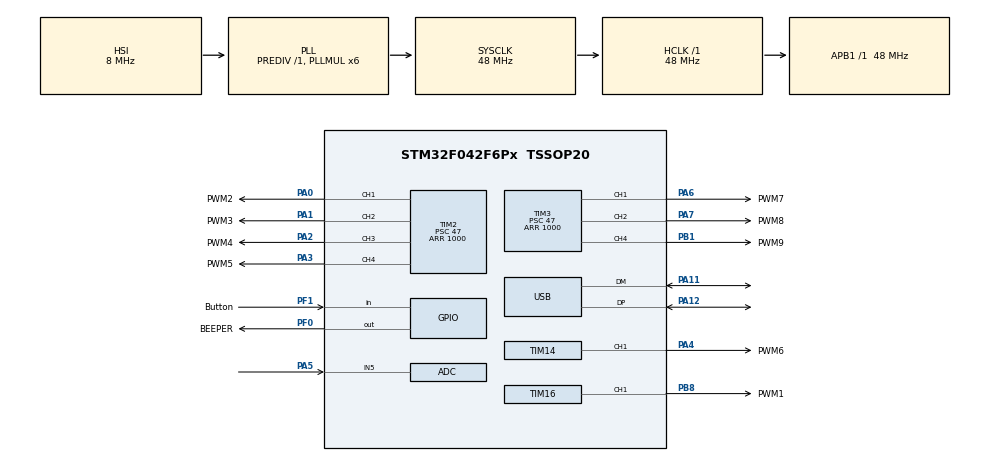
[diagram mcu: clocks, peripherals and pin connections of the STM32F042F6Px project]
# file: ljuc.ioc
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ADC.ContinuousConvMode=DISABLE
ADC.Rank=ADC_RANK_CHANNEL_NUMBER
ADC.SamplingTime=ADC_SAMPLETIME_239CYCLES_5
Dma.ADC.0.Direction=DMA_PERIPH_TO_MEMORY
Dma.ADC.0.Instance=DMA1_Channel1
Dma.ADC.0.MemDataAlignment=DMA_MDATAALIGN_WORD
Dma.ADC.0.MemInc=DMA_MINC_ENABLE
Dma.ADC.0.Mode=DMA_NORMAL
Dma.ADC.0.PeriphDataAlignment=DMA_PDATAALIGN_HALFWORD
Dma.ADC.0.PeriphInc=DMA_PINC_DISABLE
Dma.ADC.0.Priority=DMA_PRIORITY_LOW
Dma.Request0=ADC
Mcu.Family=STM32F0
Mcu.Name=STM32F042F6Px
Mcu.Package=TSSOP20
NVIC.DMA1_Channel1_IRQn=true\:0\:0\:false\:false\:true
NVIC.TIM17_IRQn=true\:0\:0\:false\:false\:true
NVIC.TIM2_IRQn=true\:0\:0\:false\:false\:true
NVIC.USB_IRQn=true\:0\:0\:false\:false\:true
PA0.GPIO_Label=PWM2
PA0.Signal=S_TIM2_CH1_ETR
PA1.GPIO_Label=PWM3
PA1.Signal=S_TIM2_CH2
PA11.Mode=Device
PA11.Signal=USB_DM
PA12.Mode=Device
PA12.Signal=USB_DP
PA13.Mode=Serial_Wire
PA13.Signal=SYS_SWDIO
PA14.Mode=Serial_Wire
PA14.Signal=SYS_SWCLK
PA2.GPIO_Label=PWM4
PA2.Signal=S_TIM2_CH3
PA3.GPIO_Label=PWM5
PA3.Signal=S_TIM2_CH4
PA4.GPIO_Label=PWM6
PA4.Signal=S_TIM14_CH1
PA5.Mode=IN5
PA5.Signal=ADC_IN5
PA6.GPIO_Label=PWM7
PA6.Signal=S_TIM3_CH1
PA7.GPIO_Label=PWM8
PA7.Signal=S_TIM3_CH2
PB1.GPIO_Label=PWM9
PB1.Signal=S_TIM3_CH4
PB8.GPIO_Label=PWM1
PB8.Signal=S_TIM16_CH1
PF0-OSC_IN.GPIO_Label=BEEPER
PF0-OSC_IN.Signal=GPIO_Output
PF1-OSC_OUT.GPIO_Label=Button
PF1-OSC_OUT.Signal=GPIO_Input
ProjectManager.HeapSize=0x200
ProjectManager.StackSize=0x400
ProjectManager.TargetToolchain=MDK-ARM V5
RCC.AHBCLKDivider=RCC_SYSCLK_DIV1
RCC.AHBFreq_Value=48000000
RCC.APB1CLKDivider=RCC_HCLK_DIV1
RCC.APB1Freq_Value=48000000
RCC.APB1TimFreq_Value=48000000
RCC.CECEnable=false
RCC.ClockTypeHCLK=RCC_CLOCKTYPE_HCLK
RCC.ClockTypePCLK1=RCC_CLOCKTYPE_PCLK1
RCC.DATA_CACHE_ENABLE=0
RCC.EnableHSE=false
RCC.EnableHSERTCDevisor=false
RCC.EnableLSE=false
RCC.EnableLSERTC=false
RCC.EnableMCOMultDivisor=false
RCC.HCLKFreq_Value=48000000
RCC.HSEState=RCC_HSE_OFF
RCC.HSI14State=RCC_HSI14_ON
RCC.HSI48State=RCC_HSI48_ON
RCC.HSIState=RCC_HSI_ON
RCC.I2C1Enable=false
RCC.INSTRUCTION_CACHE_ENABLE=0
RCC.IWDGEnable=false
RCC.LSIState=RCC_LSI_OFF
RCC.MCOEnable=false
RCC.OscillatorTypeHSI=RCC_OSCILLATORTYPE_HSI
RCC.OscillatorTypeHSI14=RCC_OSCILLATORTYPE_HSI14
RCC.OscillatorTypeHSI48=RCC_OSCILLATORTYPE_HSI48
RCC.PLLDivider=RCC_PREDIV_DIV1
RCC.PLLMUL=RCC_PLL_MUL6
RCC.PLLSource=RCC_PLLSOURCE_HSI
RCC.PLLSourceVirtual=RCC_PLLSOURCE_HSI
RCC.PLLState=RCC_PLL_ON
RCC.RTCEnable=false
RCC.SYSCLKFreq_VALUE=48000000
RCC.SYSCLKSource=RCC_SYSCLKSOURCE_PLLCLK
RCC.TimSys_Div=SYSTICK_CLKSOURCE_HCLK
RCC.USART1Enable=false
RCC.USART2Enable=false
RCC.USBClockSelection=RCC_USBCLKSOURCE_HSI48
RCC.USBEnable=true
RCC.USBFreq_Value=48000000
SH.S_TIM14_CH1.0=TIM14_CH1,PWM Generation1 CH1
SH.S_TIM16_CH1.0=TIM16_CH1,PWM Generation1 CH1
SH.S_TIM2_CH1_ETR.0=TIM2_CH1,PWM Generation1 CH1
SH.S_TIM2_CH2.0=TIM2_CH2,PWM Generation2 CH2
SH.S_TIM2_CH3.0=TIM2_CH3,PWM Generation3 CH3
SH.S_TIM2_CH4.0=TIM2_CH4,PWM Generation4 CH4
SH.S_TIM3_CH1.0=TIM3_CH1,PWM Generation1 CH1
SH.S_TIM3_CH2.0=TIM3_CH2,PWM Generation2 CH2
SH.S_TIM3_CH4.0=TIM3_CH4,PWM Generation4 CH4
TIM14.Channel=TIM_CHANNEL_1
TIM14.Period=1000
TIM14.Prescaler=47
TIM16.Channel=TIM_CHANNEL_1
TIM16.OCNIdleState_1=TIM_OCNIDLESTATE_RESET
TIM16.OCNPolarity_1=TIM_OCNPOLARITY_HIGH
TIM16.Period=1000
TIM16.Prescaler=47
TIM17.Period=9999
TIM17.Prescaler=47
TIM2.Channel-PWM\ Generation1\ CH1=TIM_CHANNEL_1
TIM2.Channel-PWM\ Generation2\ CH2=TIM_CHANNEL_2
TIM2.Channel-PWM\ Generation3\ CH3=TIM_CHANNEL_3
TIM2.Channel-PWM\ Generation4\ CH4=TIM_CHANNEL_4
TIM2.ClearInputSource=TIM_CLEARINPUTSOURCE_NONE
TIM2.ClearInputState=ENABLE
TIM2.Period=1000
TIM2.Prescaler=47
TIM3.Channel-PWM\ Generation1\ CH1=TIM_CHANNEL_1
TIM3.Channel-PWM\ Generation2\ CH2=TIM_CHANNEL_2
TIM3.Channel-PWM\ Generation4\ CH4=TIM_CHANNEL_4
TIM3.ClearInputSource=TIM_CLEARINPUTSOURCE_NONE
TIM3.ClearInputState=ENABLE
TIM3.Period=1000
TIM3.Prescaler=47
USB_DEVICE.CLASS_NAME_FS=CDC
USB_DEVICE.USBD_HandleTypeDef_FS=hUsbDevice_USB_FS
USB_DEVICE.VirtualMode=Cdc
USB_DEVICE.VirtualModeFS=Cdc_FS
VP_SYS_VS_PINREMAP.Mode=PINREMAP
VP_TIM14_VS_ClockSourceINT.Mode=Enable_Timer
VP_TIM16_VS_ClockSourceINT.Mode=Enable_Timer
VP_TIM17_VS_ClockSourceINT.Mode=Enable_Timer
VP_USB_DEVICE_VS_USB_DEVICE_CDC_FS.Mode=CDC_FS
board=ljuc

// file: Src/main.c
/**
  ******************************************************************************
  * File Name          : main.c
  * Description        : Main program body
  ******************************************************************************
  *
  * Copyright (c) 2018 STMicroelectronics International N.V.
  * All rights reserved.
  *
  * Redistribution and use in source and binary forms, with or without
  * modification, are permitted, provided that the following conditions are met:
  *
  * 1. Redistribution of source code must retain the above copyright notice,
  *    this list of conditions and the following disclaimer.
  * 2. Redistributions in binary form must reproduce the above copyright notice,
  *    this list of conditions and the following disclaimer in the documentation
  *    and/or other materials provided with the distribution.
  * 3. Neither the name of STMicroelectronics nor the names of other
  *    contributors to this software may be used to endorse or promote products
  *    derived from this software without specific written permission.
  * 4. This software, including modifications and/or derivative works of this
  *    software, must execute solely and exclusively on microcontroller or
  *    microprocessor devices manufactured by or for STMicroelectronics.
  * 5. Redistribution and use of this software other than as permitted under
  *    this license is void and will automatically terminate your rights under
  *    this license.
  *
  * THIS SOFTWARE IS PROVIDED BY STMICROELECTRONICS AND CONTRIBUTORS "AS IS"
  * AND ANY EXPRESS, IMPLIED OR STATUTORY WARRANTIES, INCLUDING, BUT NOT
  * LIMITED TO, THE IMPLIED WARRANTIES OF MERCHANTABILITY, FITNESS FOR A
  * PARTICULAR PURPOSE AND NON-INFRINGEMENT OF THIRD PARTY INTELLECTUAL PROPERTY
  * RIGHTS ARE DISCLAIMED TO THE FULLEST EXTENT PERMITTED BY LAW. IN NO EVENT
  * SHALL STMICROELECTRONICS OR CONTRIBUTORS BE LIABLE FOR ANY DIRECT, INDIRECT,
  * INCIDENTAL, SPECIAL, EXEMPLARY, OR CONSEQUENTIAL DAMAGES (INCLUDING, BUT NOT
  * LIMITED TO, PROCUREMENT OF SUBSTITUTE GOODS OR SERVICES; LOSS OF USE, DATA,
  * OR PROFITS; OR BUSINESS INTERRUPTION) HOWEVER CAUSED AND ON ANY THEORY OF
  * LIABILITY, WHETHER IN CONTRACT, STRICT LIABILITY, OR TORT (INCLUDING
  * NEGLIGENCE OR OTHERWISE) ARISING IN ANY WAY OUT OF THE USE OF THIS SOFTWARE,
  * EVEN IF ADVISED OF THE POSSIBILITY OF SUCH DAMAGE.
  *
  ******************************************************************************
  */
#include "main.h"
#include "stm32f0xx_hal.h"
#include "usb_device.h"

ADC_HandleTypeDef hadc;
DMA_HandleTypeDef hdma_adc;

TIM_HandleTypeDef htim2;
TIM_HandleTypeDef htim3;
TIM_HandleTypeDef htim14;
TIM_HandleTypeDef htim16;
TIM_HandleTypeDef htim17;

/* USER CODE BEGIN PV */
/* Private variables ---------------------------------------------------------*/
uint8_t i = 0;
/* USER CODE END PV */

void SystemClock_Config(void);
void Error_Handler(void);
static void MX_GPIO_Init(void);
static void MX_DMA_Init(void);
static void MX_TIM2_Init(void);
static void MX_TIM3_Init(void);
static void MX_TIM14_Init(void);
static void MX_TIM16_Init(void);
static void MX_TIM17_Init(void);
static void MX_ADC_Init(void);

void HAL_TIM_MspPostInit(TIM_HandleTypeDef *htim);

/* USER CODE BEGIN PFP */
/* Private function prototypes -----------------------------------------------*/

/* USER CODE END PFP */

int main(void)

{

  /* MCU Configuration----------------------------------------------------------*/

  /* Reset of all peripherals, Initializes the Flash interface and the Systick. */
  HAL_Init();

  /* Configure the system clock */
  SystemClock_Config();

  /* Initialize all configured peripherals */
  MX_GPIO_Init();
  MX_DMA_Init();
  MX_TIM2_Init();
  MX_TIM3_Init();
  MX_TIM14_Init();
  MX_TIM16_Init();
  MX_TIM17_Init();
  MX_ADC_Init();
  MX_USB_DEVICE_Init();

  /* USER CODE BEGIN 2 */

	HAL_TIM_PWM_Start(&htim2,TIM_CHANNEL_1);
	HAL_TIM_PWM_Start(&htim2,TIM_CHANNEL_2);
	HAL_TIM_PWM_Start(&htim2,TIM_CHANNEL_3);
	HAL_TIM_PWM_Start(&htim2,TIM_CHANNEL_4);
	HAL_TIM_PWM_Start(&htim16,TIM_CHANNEL_1);
	HAL_TIM_PWM_Start(&htim14,TIM_CHANNEL_1);
	HAL_TIM_PWM_Start(&htim3,TIM_CHANNEL_1);
	HAL_TIM_PWM_Start(&htim3,TIM_CHANNEL_2);
	HAL_TIM_PWM_Start(&htim3,TIM_CHANNEL_4);

	HAL_TIM_Base_Start_IT(&htim17);

	HAL_Delay(500);

  /* USER CODE END 2 */

  /* Infinite loop */
  /* USER CODE BEGIN WHILE */
  while (1)
  {
//		i=0x69;
//		CDC_Transmit_FS(&i,1);
//		HAL_Delay(100);
  /* USER CODE END WHILE */

  }

}

/** System Clock Configuration
*/
void SystemClock_Config(void)
{

  RCC_OscInitTypeDef RCC_OscInitStruct;
  RCC_ClkInitTypeDef RCC_ClkInitStruct;
  RCC_PeriphCLKInitTypeDef PeriphClkInit;

    /**Initializes the CPU, AHB and APB busses clocks
    */
  RCC_OscInitStruct.OscillatorType = RCC_OSCILLATORTYPE_HSI|RCC_OSCILLATORTYPE_HSI14
                              |RCC_OSCILLATORTYPE_HSI48;
  RCC_OscInitStruct.HSIState = RCC_HSI_ON;
  RCC_OscInitStruct.HSI48State = RCC_HSI48_ON;
  RCC_OscInitStruct.HSI14State = RCC_HSI14_ON;
  RCC_OscInitStruct.HSICalibrationValue = 16;
  RCC_OscInitStruct.HSI14CalibrationValue = 16;
  RCC_OscInitStruct.PLL.PLLState = RCC_PLL_ON;
  RCC_OscInitStruct.PLL.PLLSource = RCC_PLLSOURCE_HSI;
  RCC_OscInitStruct.PLL.PLLMUL = RCC_PLL_MUL6;
  RCC_OscInitStruct.PLL.PREDIV = RCC_PREDIV_DIV1;
  if (HAL_RCC_OscConfig(&RCC_OscInitStruct) != HAL_OK)
  {
    Error_Handler();
  }

    /**Initializes the CPU, AHB and APB busses clocks
    */
  RCC_ClkInitStruct.ClockType = RCC_CLOCKTYPE_HCLK|RCC_CLOCKTYPE_SYSCLK
                              |RCC_CLOCKTYPE_PCLK1;
  RCC_ClkInitStruct.SYSCLKSource = RCC_SYSCLKSOURCE_PLLCLK;
  RCC_ClkInitStruct.AHBCLKDivider = RCC_SYSCLK_DIV1;
  RCC_ClkInitStruct.APB1CLKDivider = RCC_HCLK_DIV1;

  if (HAL_RCC_ClockConfig(&RCC_ClkInitStruct, FLASH_LATENCY_1) != HAL_OK)
  {
    Error_Handler();
  }

  PeriphClkInit.PeriphClockSelection = RCC_PERIPHCLK_USB;
  PeriphClkInit.UsbClockSelection = RCC_USBCLKSOURCE_HSI48;

  if (HAL_RCCEx_PeriphCLKConfig(&PeriphClkInit) != HAL_OK)
  {
    Error_Handler();
  }

    /**Configure the Systick interrupt time
    */
  HAL_SYSTICK_Config(HAL_RCC_GetHCLKFreq()/1000);

    /**Configure the Systick
    */
  HAL_SYSTICK_CLKSourceConfig(SYSTICK_CLKSOURCE_HCLK);

  /* SysTick_IRQn interrupt configuration */
  HAL_NVIC_SetPriority(SysTick_IRQn, 0, 0);
}

/* ADC init function */
static void MX_ADC_Init(void)
{

  ADC_ChannelConfTypeDef sConfig;

    /**Configure the global features of the ADC (Clock, Resolution, Data Alignment and number of conversion)
    */
  hadc.Instance = ADC1;
  hadc.Init.ClockPrescaler = ADC_CLOCK_ASYNC_DIV1;
  hadc.Init.Resolution = ADC_RESOLUTION_12B;
  hadc.Init.DataAlign = ADC_DATAALIGN_RIGHT;
  hadc.Init.ScanConvMode = ADC_SCAN_DIRECTION_FORWARD;
  hadc.Init.EOCSelection = ADC_EOC_SINGLE_CONV;
  hadc.Init.LowPowerAutoWait = DISABLE;
  hadc.Init.LowPowerAutoPowerOff = DISABLE;
  hadc.Init.ContinuousConvMode = DISABLE;
  hadc.Init.DiscontinuousConvMode = DISABLE;
  hadc.Init.ExternalTrigConv = ADC_SOFTWARE_START;
  hadc.Init.ExternalTrigConvEdge = ADC_EXTERNALTRIGCONVEDGE_NONE;
  hadc.Init.DMAContinuousRequests = DISABLE;
  hadc.Init.Overrun = ADC_OVR_DATA_PRESERVED;
  if (HAL_ADC_Init(&hadc) != HAL_OK)
  {
    Error_Handler();
  }

    /**Configure for the selected ADC regular channel to be converted.
    */
  sConfig.Channel = ADC_CHANNEL_5;
  sConfig.Rank = ADC_RANK_CHANNEL_NUMBER;
  sConfig.SamplingTime = ADC_SAMPLETIME_239CYCLES_5;
  if (HAL_ADC_ConfigChannel(&hadc, &sConfig) != HAL_OK)
  {
    Error_Handler();
  }

}

/* TIM2 init function */
static void MX_TIM2_Init(void)
{

  TIM_MasterConfigTypeDef sMasterConfig;
  TIM_OC_InitTypeDef sConfigOC;

  htim2.Instance = TIM2;
  htim2.Init.Prescaler = 47;
  htim2.Init.CounterMode = TIM_COUNTERMODE_UP;
  htim2.Init.Period = 1000;
  htim2.Init.ClockDivision = TIM_CLOCKDIVISION_DIV1;
  htim2.Init.AutoReloadPreload = TIM_AUTORELOAD_PRELOAD_DISABLE;
  if (HAL_TIM_PWM_Init(&htim2) != HAL_OK)
  {
    Error_Handler();
  }

  sMasterConfig.MasterOutputTrigger = TIM_TRGO_RESET;
  sMasterConfig.MasterSlaveMode = TIM_MASTERSLAVEMODE_DISABLE;
  if (HAL_TIMEx_MasterConfigSynchronization(&htim2, &sMasterConfig) != HAL_OK)
  {
    Error_Handler();
  }

  sConfigOC.OCMode = TIM_OCMODE_PWM1;
  sConfigOC.Pulse = 0;
  sConfigOC.OCPolarity = TIM_OCPOLARITY_HIGH;
  sConfigOC.OCFastMode = TIM_OCFAST_DISABLE;
  if (HAL_TIM_PWM_ConfigChannel(&htim2, &sConfigOC, TIM_CHANNEL_1) != HAL_OK)
  {
    Error_Handler();
  }

  if (HAL_TIM_PWM_ConfigChannel(&htim2, &sConfigOC, TIM_CHANNEL_2) != HAL_OK)
  {
    Error_Handler();
  }

  if (HAL_TIM_PWM_ConfigChannel(&htim2, &sConfigOC, TIM_CHANNEL_3) != HAL_OK)
  {
    Error_Handler();
  }

  if (HAL_TIM_PWM_ConfigChannel(&htim2, &sConfigOC, TIM_CHANNEL_4) != HAL_OK)
  {
    Error_Handler();
  }

  HAL_TIM_MspPostInit(&htim2);

}

/* TIM3 init function */
static void MX_TIM3_Init(void)
{

  TIM_MasterConfigTypeDef sMasterConfig;
  TIM_OC_InitTypeDef sConfigOC;

  htim3.Instance = TIM3;
  htim3.Init.Prescaler = 47;
  htim3.Init.CounterMode = TIM_COUNTERMODE_UP;
  htim3.Init.Period = 1000;
  htim3.Init.ClockDivision = TIM_CLOCKDIVISION_DIV1;
  htim3.Init.AutoReloadPreload = TIM_AUTORELOAD_PRELOAD_DISABLE;
  if (HAL_TIM_PWM_Init(&htim3) != HAL_OK)
  {
    Error_Handler();
  }

  sMasterConfig.MasterOutputTrigger = TIM_TRGO_RESET;
  sMasterConfig.MasterSlaveMode = TIM_MASTERSLAVEMODE_DISABLE;
  if (HAL_TIMEx_MasterConfigSynchronization(&htim3, &sMasterConfig) != HAL_OK)
  {
    Error_Handler();
  }

  sConfigOC.OCMode = TIM_OCMODE_PWM1;
  sConfigOC.Pulse = 0;
  sConfigOC.OCPolarity = TIM_OCPOLARITY_HIGH;
  sConfigOC.OCFastMode = TIM_OCFAST_DISABLE;
  if (HAL_TIM_PWM_ConfigChannel(&htim3, &sConfigOC, TIM_CHANNEL_1) != HAL_OK)
  {
    Error_Handler();
  }

  if (HAL_TIM_PWM_ConfigChannel(&htim3, &sConfigOC, TIM_CHANNEL_2) != HAL_OK)
  {
    Error_Handler();
  }

  if (HAL_TIM_PWM_ConfigChannel(&htim3, &sConfigOC, TIM_CHANNEL_4) != HAL_OK)
  {
    Error_Handler();
  }

  HAL_TIM_MspPostInit(&htim3);

}

/* TIM14 init function */
static void MX_TIM14_Init(void)
{

  TIM_OC_InitTypeDef sConfigOC;

  htim14.Instance = TIM14;
  htim14.Init.Prescaler = 47;
  htim14.Init.CounterMode = TIM_COUNTERMODE_UP;
  htim14.Init.Period = 1000;
  htim14.Init.ClockDivision = TIM_CLOCKDIVISION_DIV1;
  htim14.Init.AutoReloadPreload = TIM_AUTORELOAD_PRELOAD_DISABLE;
  if (HAL_TIM_Base_Init(&htim14) != HAL_OK)
  {
    Error_Handler();
  }

  if (HAL_TIM_PWM_Init(&htim14) != HAL_OK)
  {
    Error_Handler();
  }

  sConfigOC.OCMode = TIM_OCMODE_PWM1;
  sConfigOC.Pulse = 0;
  sConfigOC.OCPolarity = TIM_OCPOLARITY_HIGH;
  sConfigOC.OCFastMode = TIM_OCFAST_DISABLE;
  if (HAL_TIM_PWM_ConfigChannel(&htim14, &sConfigOC, TIM_CHANNEL_1) != HAL_OK)
  {
    Error_Handler();
  }

  HAL_TIM_MspPostInit(&htim14);

}

/* TIM16 init function */
static void MX_TIM16_Init(void)
{

  TIM_OC_InitTypeDef sConfigOC;
  TIM_BreakDeadTimeConfigTypeDef sBreakDeadTimeConfig;

  htim16.Instance = TIM16;
  htim16.Init.Prescaler = 47;
  htim16.Init.CounterMode = TIM_COUNTERMODE_UP;
  htim16.Init.Period = 1000;
  htim16.Init.ClockDivision = TIM_CLOCKDIVISION_DIV1;
  htim16.Init.RepetitionCounter = 0;
  htim16.Init.AutoReloadPreload = TIM_AUTORELOAD_PRELOAD_DISABLE;
  if (HAL_TIM_Base_Init(&htim16) != HAL_OK)
  {
    Error_Handler();
  }

  if (HAL_TIM_PWM_Init(&htim16) != HAL_OK)
  {
    Error_Handler();
  }

  sConfigOC.OCMode = TIM_OCMODE_PWM1;
  sConfigOC.Pulse = 0;
  sConfigOC.OCPolarity = TIM_OCPOLARITY_HIGH;
  sConfigOC.OCNPolarity = TIM_OCNPOLARITY_HIGH;
  sConfigOC.OCFastMode = TIM_OCFAST_DISABLE;
  sConfigOC.OCIdleState = TIM_OCIDLESTATE_RESET;
  sConfigOC.OCNIdleState = TIM_OCNIDLESTATE_RESET;
  if (HAL_TIM_PWM_ConfigChannel(&htim16, &sConfigOC, TIM_CHANNEL_1) != HAL_OK)
  {
    Error_Handler();
  }

  sBreakDeadTimeConfig.OffStateRunMode = TIM_OSSR_DISABLE;
  sBreakDeadTimeConfig.OffStateIDLEMode = TIM_OSSI_DISABLE;
  sBreakDeadTimeConfig.LockLevel = TIM_LOCKLEVEL_OFF;
  sBreakDeadTimeConfig.DeadTime = 0;
  sBreakDeadTimeConfig.BreakState = TIM_BREAK_DISABLE;
  sBreakDeadTimeConfig.BreakPolarity = TIM_BREAKPOLARITY_HIGH;
  sBreakDeadTimeConfig.AutomaticOutput = TIM_AUTOMATICOUTPUT_DISABLE;
  if (HAL_TIMEx_ConfigBreakDeadTime(&htim16, &sBreakDeadTimeConfig) != HAL_OK)
  {
    Error_Handler();
  }

  HAL_TIM_MspPostInit(&htim16);

}

/* TIM17 init function */
static void MX_TIM17_Init(void)
{

  htim17.Instance = TIM17;
  htim17.Init.Prescaler = 47;
  htim17.Init.CounterMode = TIM_COUNTERMODE_UP;
  htim17.Init.Period = 99;
  htim17.Init.ClockDivision = TIM_CLOCKDIVISION_DIV1;
  htim17.Init.RepetitionCounter = 0;
  htim17.Init.AutoReloadPreload = TIM_AUTORELOAD_PRELOAD_DISABLE;
  if (HAL_TIM_Base_Init(&htim17) != HAL_OK)
  {
    Error_Handler();
  }

}

static void MX_DMA_Init(void)
{
  /* DMA controller clock enable */
  __HAL_RCC_DMA1_CLK_ENABLE();

  /* DMA interrupt init */
  /* DMA1_Channel1_IRQn interrupt configuration */
  HAL_NVIC_SetPriority(DMA1_Channel1_IRQn, 0, 0);
  HAL_NVIC_EnableIRQ(DMA1_Channel1_IRQn);

}

/** Configure pins as
        * Analog
        * Input
        * Output
        * EVENT_OUT
        * EXTI
*/
static void MX_GPIO_Init(void)
{

  GPIO_InitTypeDef GPIO_InitStruct;

  /* GPIO Ports Clock Enable */
  __HAL_RCC_GPIOB_CLK_ENABLE();
  __HAL_RCC_GPIOF_CLK_ENABLE();
  __HAL_RCC_GPIOA_CLK_ENABLE();

  /*Configure GPIO pin Output Level */
  HAL_GPIO_WritePin(BEEPER_GPIO_Port, BEEPER_Pin, GPIO_PIN_RESET);

  /*Configure GPIO pin : BEEPER_Pin */
  GPIO_InitStruct.Pin = BEEPER_Pin;
  GPIO_InitStruct.Mode = GPIO_MODE_OUTPUT_PP;
  GPIO_InitStruct.Pull = GPIO_NOPULL;
  GPIO_InitStruct.Speed = GPIO_SPEED_FREQ_LOW;
  HAL_GPIO_Init(BEEPER_GPIO_Port, &GPIO_InitStruct);

  /*Configure GPIO pin : Button_Pin */
  GPIO_InitStruct.Pin = Button_Pin;
  GPIO_InitStruct.Mode = GPIO_MODE_INPUT;
  GPIO_InitStruct.Pull = GPIO_NOPULL;
  HAL_GPIO_Init(Button_GPIO_Port, &GPIO_InitStruct);

}

void Error_Handler(void)
{
  while(1)
  {
  }
}

/************************ (C) COPYRIGHT STMicroelectronics *****END OF FILE****/
